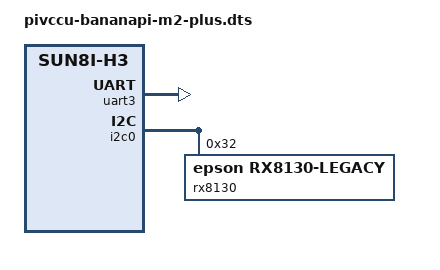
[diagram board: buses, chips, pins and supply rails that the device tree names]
/dts-v1/;
/plugin/;

/ {
  compatible = "allwinner,sun8i-h3";

  fragment@0 {
    target = <&uart3>;
    __overlay__ {
      pinctrl-names = "default";
      pinctrl-0 = <&uart3_pins>;
      status = "okay";
      compatible = "pivccu,dw_apb";
      pivccu,reset_pin = <&pio 0 16 0>;
      pivccu,alt_reset_pin = <&pio 0 10 0>;
      pivccu,red_pin = <&pio 7 4 0>;
      pivccu,green_pin = <&pio 0 21 0>;
      pivccu,blue_pin = <&pio 0 20 0>;
      pivccu,rtc = <&rpi_rf_mod_rtc>;
    };
  };


  fragment@1 {
    target = <&i2c0>;
    __overlay__ {
      #address-cells = <1>;
      #size-cells = <0>;
      status = "okay";

      rx8130@32 {
        compatible = "epson,rx8130-legacy";
        reg = <0x32>;
        status = "okay";
        enable-external-capacitor;
      };
    };
  };
};
